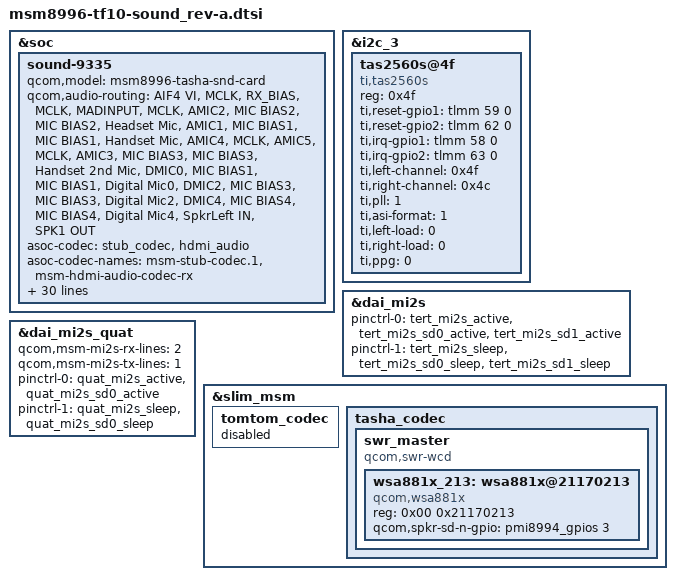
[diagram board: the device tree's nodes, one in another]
/* Copyright (c) 2015, The Linux Foundation. All rights reserved.
 *
 * This program is free software; you can redistribute it and/or modify
 * it under the terms of the GNU General Public License version 2 and
 * only version 2 as published by the Free Software Foundation.
 *
 * This program is distributed in the hope that it will be useful,
 * but WITHOUT ANY WARRANTY; without even the implied warranty of
 * MERCHANTABILITY or FITNESS FOR A PARTICULAR PURPOSE.  See the
 * GNU General Public License for more details.
 */

&soc {
	sound-9335 {
		qcom,model = "msm8996-tasha-snd-card";

		qcom,audio-routing =
			"AIF4 VI", "MCLK",
			"RX_BIAS", "MCLK",
			"MADINPUT", "MCLK",
			"AMIC2", "MIC BIAS2",
			"MIC BIAS2", "Headset Mic",
			"AMIC1", "MIC BIAS1",
			"MIC BIAS1", "Handset Mic",
			"AMIC4", "MCLK",
			"AMIC5", "MCLK",
			"AMIC3", "MIC BIAS3",
			"MIC BIAS3", "Handset 2nd Mic",
			"DMIC0", "MIC BIAS1",
			"MIC BIAS1", "Digital Mic0",
			"DMIC2", "MIC BIAS3",
			"MIC BIAS3", "Digital Mic2",
			"DMIC4", "MIC BIAS4",
			"MIC BIAS4", "Digital Mic4",
			"SpkrLeft IN", "SPK1 OUT";

		asoc-codec = <&stub_codec>, <&hdmi_audio>;
		asoc-codec-names = "msm-stub-codec.1", "msm-hdmi-audio-codec-rx";
		asoc-cpu = <&dai_pri_auxpcm>, <&dai_sec_auxpcm>, <&dai_hdmi>, <&dai_mi2s_sec>, <&dai_mi2s>,<&dai_mi2s_quat>,
			<&sb_0_rx>, <&sb_0_tx>, <&sb_1_rx>, <&sb_1_tx>,
			<&sb_2_rx>, <&sb_2_tx>, <&sb_3_rx>, <&sb_3_tx>,
			<&sb_4_rx>, <&sb_4_tx>, <&sb_5_tx>, <&afe_pcm_rx>,
			<&afe_pcm_tx>, <&afe_proxy_rx>, <&afe_proxy_tx>,
			<&incall_record_rx>, <&incall_record_tx>,
			<&incall_music_rx>, <&incall_music2_rx>,
			<&sb_5_rx>, <&sb_6_rx>,
			<&usb_audio_rx>, <&usb_audio_tx>;
		asoc-cpu-names = "msm-dai-q6-auxpcm.1", "msm-dai-q6-auxpcm.2",
			"msm-dai-q6-hdmi.8", "msm-dai-q6-mi2s.1","msm-dai-q6-mi2s.2","msm-dai-q6-mi2s.3",
			"msm-dai-q6-dev.16384", "msm-dai-q6-dev.16385",
			"msm-dai-q6-dev.16386", "msm-dai-q6-dev.16387",
			"msm-dai-q6-dev.16388", "msm-dai-q6-dev.16389",
			"msm-dai-q6-dev.16390", "msm-dai-q6-dev.16391",
			"msm-dai-q6-dev.16392", "msm-dai-q6-dev.16393",
			"msm-dai-q6-dev.16395", "msm-dai-q6-dev.224",
			"msm-dai-q6-dev.225", "msm-dai-q6-dev.241",
			"msm-dai-q6-dev.240", "msm-dai-q6-dev.32771",
			"msm-dai-q6-dev.32772", "msm-dai-q6-dev.32773",
			"msm-dai-q6-dev.32770", "msm-dai-q6-dev.16394",
			"msm-dai-q6-dev.16396",
			"msm-dai-q6-dev.28672", "msm-dai-q6-dev.28673";
		qcom,wsa-max-devs = <0>;
		lge,tas2560-codec;
		qcom,wsa-devs = <&wsa881x_213>;
		qcom,wsa-aux-dev-prefix = "SpkrLeft";
		qcom,msm-mbhc-hphl-swh = <1>;
		qcom,mbhc-audio-jack-type = "4-pole-jack";
	};
};

&i2c_3 {
	tas2560s@4f {
		status = "ok";
		compatible = "ti,tas2560s";
		reg = <0x4f>;
		ti,reset-gpio1 = <&tlmm 59 0>;
		ti,reset-gpio2 = <&tlmm 62 0>;
		ti,irq-gpio1 = <&tlmm 58 0>;
		ti,irq-gpio2 = <&tlmm 63 0>;
		ti,left-channel = <0x4f>;
		ti,right-channel = <0x4c>;
		ti,pll = <1>; /* refer to tas2560.h for more details */
		ti,asi-format = <1>; /* 0, i2S; 1, DSP;  */
		ti,left-load = <0>; /* 0, 8Ohm; 1, 6Ohm; 2, 4Ohm */
		ti,right-load = <0>; /* 0, 8Ohm; 1, 6Ohm; 2, 4Ohm */
		ti,ppg = <0>; /* 0, 0dB default; 1. enable -2dB */
	};
};

&dai_mi2s {
	pinctrl-names = "default", "idle";
	pinctrl-0 = <&tert_mi2s_active &tert_mi2s_sd0_active &tert_mi2s_sd1_active>;
	pinctrl-1 = <&tert_mi2s_sleep &tert_mi2s_sd0_sleep &tert_mi2s_sd1_sleep>;
};

&dai_mi2s_quat {
	qcom,msm-mi2s-rx-lines = <2>; /* SD0 (1 << 0) | SD1 (1 << 1) | SD2 (1 << 2) */
	qcom,msm-mi2s-tx-lines = <1>; /* SD2 (1 << 3) */
	pinctrl-names = "default", "sleep";
	pinctrl-0 = <&quat_mi2s_active &quat_mi2s_sd0_active>;
	pinctrl-1 = <&quat_mi2s_sleep &quat_mi2s_sd0_sleep>;
};

&slim_msm {
	tomtom_codec {
		status = "disabled";
	};
	tasha_codec {
		swr_master {
			compatible = "qcom,swr-wcd";
			#address-cells = <2>;
			#size-cells = <0>;

			wsa881x_213: wsa881x@21170213 {
				compatible = "qcom,wsa881x";
				reg = <0x00 0x21170213>;
				qcom,spkr-sd-n-gpio = <&pmi8994_gpios 3 0>;
			};
		};
	};
};
